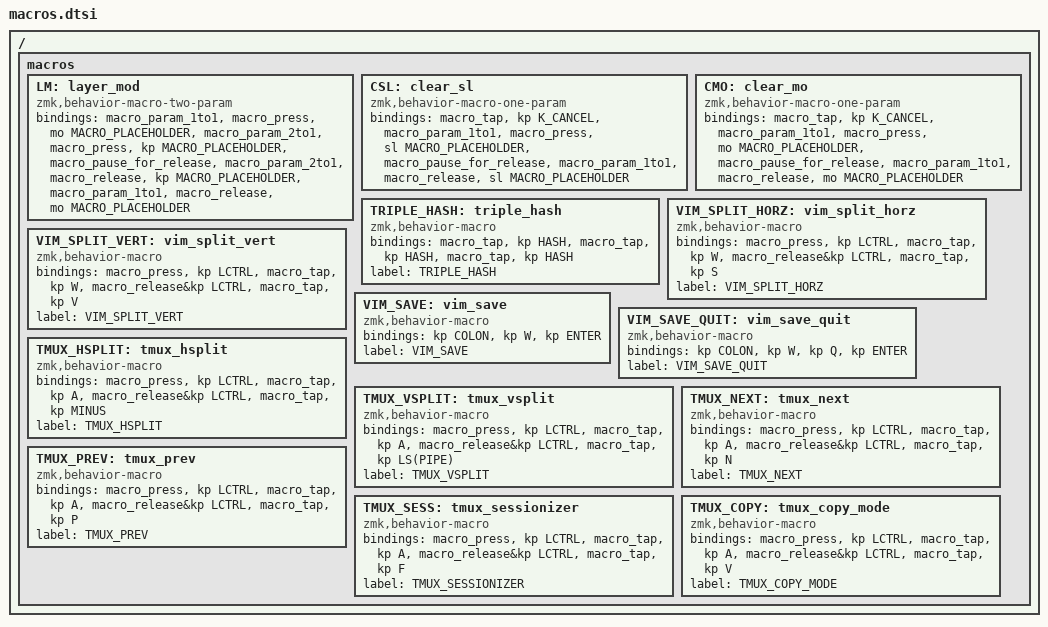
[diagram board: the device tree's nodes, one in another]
/ {
  macros {

    /* ───────────  Short-layer/clear helpers supplied by ZMK  ─────────── */
    LM: layer_mod    { compatible = "zmk,behavior-macro-two-param"; #binding-cells = <2>;
                       bindings = <&macro_param_1to1>, <&macro_press &mo MACRO_PLACEHOLDER>,
                                  <&macro_param_2to1>, <&macro_press &kp MACRO_PLACEHOLDER>,
                                  <&macro_pause_for_release>,
                                  <&macro_param_2to1>, <&macro_release &kp MACRO_PLACEHOLDER>,
                                  <&macro_param_1to1>, <&macro_release &mo MACRO_PLACEHOLDER>; };

    CSL: clear_sl    { compatible = "zmk,behavior-macro-one-param";  #binding-cells = <1>;
                       bindings = <&macro_tap &kp K_CANCEL>, <&macro_param_1to1>,
                                  <&macro_press &sl MACRO_PLACEHOLDER>,
                                  <&macro_pause_for_release>,
                                  <&macro_param_1to1>, <&macro_release &sl MACRO_PLACEHOLDER>; };

    CMO: clear_mo    { compatible = "zmk,behavior-macro-one-param";  #binding-cells = <1>;
                       bindings = <&macro_tap &kp K_CANCEL>, <&macro_param_1to1>,
                                  <&macro_press &mo MACRO_PLACEHOLDER>,
                                  <&macro_pause_for_release>,
                                  <&macro_param_1to1>, <&macro_release &mo MACRO_PLACEHOLDER>; };


    TRIPLE_HASH: triple_hash {
      compatible = "zmk,behavior-macro";
      #binding-cells = <0>;
      bindings = 
        <&macro_tap &kp HASH>,
        <&macro_tap &kp HASH>,
        <&macro_tap &kp HASH>;
      label = "TRIPLE_HASH";
    };

    /* ───────────  Vim helpers  ─────────── */

    VIM_SPLIT_HORZ: vim_split_horz {
        compatible     = "zmk,behavior-macro"; #binding-cells = <0>;
        bindings = < &macro_press  &kp LCTRL >,
                   < &macro_tap    &kp W     >,
                   < &macro_release&kp LCTRL>,
                   < &macro_tap    &kp S     >;
        label = "VIM_SPLIT_HORZ";
    };

    VIM_SPLIT_VERT: vim_split_vert {
        compatible     = "zmk,behavior-macro"; #binding-cells = <0>;
        bindings = < &macro_press  &kp LCTRL >,
                   < &macro_tap    &kp W     >,
                   < &macro_release&kp LCTRL>,
                   < &macro_tap    &kp V     >;
        label = "VIM_SPLIT_VERT";
    };

    VIM_SAVE: vim_save {
        compatible     = "zmk,behavior-macro"; #binding-cells = <0>;
        bindings = < &kp COLON >,
                  < &kp W >,
                  < &kp ENTER >;
        label = "VIM_SAVE";
    };

    VIM_SAVE_QUIT: vim_save_quit {
        compatible     = "zmk,behavior-macro"; #binding-cells = <0>;
        bindings = < &kp COLON >,
                  < &kp W >,
                  < &kp Q >,
                  < &kp ENTER >;
        label = "VIM_SAVE_QUIT";
    };

    /* ───────────  Tmux helpers (prefix = Ctrl-A)  ─────────── */

    TMUX_HSPLIT: tmux_hsplit {
        compatible     = "zmk,behavior-macro"; #binding-cells = <0>;
        bindings = < &macro_press  &kp LCTRL >,
                   < &macro_tap    &kp A     >,
                   < &macro_release&kp LCTRL>,
                   < &macro_tap    &kp MINUS >;
        label = "TMUX_HSPLIT";
    };

    TMUX_VSPLIT: tmux_vsplit {
        compatible     = "zmk,behavior-macro"; #binding-cells = <0>;
        bindings = < &macro_press  &kp LCTRL >,
                   < &macro_tap    &kp A     >,
                   < &macro_release&kp LCTRL>,
                   < &macro_tap    &kp LS(PIPE) >;
        label = "TMUX_VSPLIT";
    };

    TMUX_NEXT: tmux_next {
        compatible     = "zmk,behavior-macro"; #binding-cells = <0>;
        bindings = < &macro_press  &kp LCTRL >,
                   < &macro_tap    &kp A     >,
                   < &macro_release&kp LCTRL>,
                   < &macro_tap    &kp N     >;
        label = "TMUX_NEXT";
    };

    TMUX_PREV: tmux_prev {
        compatible     = "zmk,behavior-macro"; #binding-cells = <0>;
        bindings = < &macro_press  &kp LCTRL >,
                   < &macro_tap    &kp A     >,
                   < &macro_release&kp LCTRL>,
                   < &macro_tap    &kp P     >;
        label = "TMUX_PREV";
    };

    TMUX_SESS: tmux_sessionizer {
        compatible     = "zmk,behavior-macro"; #binding-cells = <0>;
        bindings = < &macro_press  &kp LCTRL >,
                   < &macro_tap    &kp A     >,
                   < &macro_release&kp LCTRL>,
                   < &macro_tap    &kp F     >;
        label = "TMUX_SESSIONIZER";
    };

    TMUX_COPY: tmux_copy_mode {
        compatible     = "zmk,behavior-macro"; #binding-cells = <0>;
        bindings = < &macro_press  &kp LCTRL >,
                   < &macro_tap    &kp A     >,
                   < &macro_release&kp LCTRL>,
                   < &macro_tap    &kp V     >;
        label = "TMUX_COPY_MODE";
    };
  };
};
